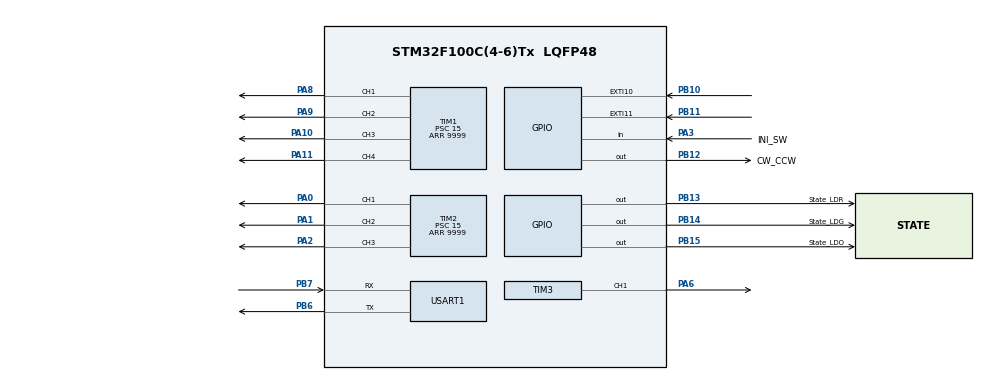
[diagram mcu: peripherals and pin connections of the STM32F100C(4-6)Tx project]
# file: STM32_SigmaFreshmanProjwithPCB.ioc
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Mcu.Family=STM32F1
Mcu.Name=STM32F100C(4-6)Tx
Mcu.Package=LQFP48
NVIC.EXTI15_10_IRQn=true\:0\:0\:false\:false\:true
NVIC.PriorityGroup=NVIC_PRIORITYGROUP_4
NVIC.TIM1_BRK_TIM15_IRQn=true\:0\:0\:false\:false\:true
NVIC.TIM1_UP_TIM16_IRQn=true\:0\:0\:false\:false\:true
NVIC.TIM2_IRQn=true\:0\:0\:false\:false\:true
NVIC.TIM3_IRQn=true\:0\:0\:false\:false\:true
NVIC.USART1_IRQn=true\:0\:0\:false\:false\:true
PA0-WKUP.Signal=S_TIM2_CH1_ETR
PA1.Signal=S_TIM2_CH2
PA10.Signal=S_TIM1_CH3
PA11.Signal=S_TIM1_CH4
PA13.Mode=Serial_Wire
PA13.Signal=SYS_JTMS-SWDIO
PA14.Mode=Serial_Wire
PA14.Signal=SYS_JTCK-SWCLK
PA2.Signal=S_TIM2_CH3
PA3.GPIO_Label=INI_SW
PA3.Signal=GPIO_Input
PA6.Signal=S_TIM3_CH1
PA8.Signal=S_TIM1_CH1
PA9.Signal=S_TIM1_CH2
PB10.GPIO_PuPd=GPIO_PULLUP
PB10.Signal=GPXTI10
PB11.GPIO_PuPd=GPIO_PULLUP
PB11.Signal=GPXTI11
PB12.GPIO_Label=CW_CCW
PB12.Signal=GPIO_Output
PB13.GPIO_Label=State_LDR
PB13.Signal=GPIO_Output
PB14.GPIO_Label=State_LDG
PB14.Signal=GPIO_Output
PB15.GPIO_Label=State_LDO
PB15.Signal=GPIO_Output
PB6.Mode=Asynchronous
PB6.Signal=USART1_TX
PB7.Mode=Asynchronous
PB7.Signal=USART1_RX
ProjectManager.HeapSize=0x200
ProjectManager.StackSize=0x400
ProjectManager.TargetToolchain=EWARM
RCC.APB1Freq_Value=8000000
RCC.APB2Freq_Value=8000000
SH.S_TIM1_CH1.0=TIM1_CH1,PWM Generation1 CH1
SH.S_TIM1_CH2.0=TIM1_CH2,PWM Generation2 CH2
SH.S_TIM1_CH3.0=TIM1_CH3,PWM Generation3 CH3
SH.S_TIM1_CH4.0=TIM1_CH4,PWM Generation4 CH4
SH.S_TIM2_CH1_ETR.0=TIM2_CH1,PWM Generation1 CH1
SH.S_TIM2_CH2.0=TIM2_CH2,PWM Generation2 CH2
SH.S_TIM2_CH3.0=TIM2_CH3,PWM Generation3 CH3
SH.S_TIM3_CH1.0=TIM3_CH1,PWM Generation1 CH1
TIM1.Channel-PWM\ Generation1\ CH1=TIM_CHANNEL_1
TIM1.Channel-PWM\ Generation2\ CH2=TIM_CHANNEL_2
TIM1.Channel-PWM\ Generation3\ CH3=TIM_CHANNEL_3
TIM1.Channel-PWM\ Generation4\ CH4=TIM_CHANNEL_4
TIM1.Period=9999
TIM1.Prescaler=15
TIM2.Channel-PWM\ Generation1\ CH1=TIM_CHANNEL_1
TIM2.Channel-PWM\ Generation2\ CH2=TIM_CHANNEL_2
TIM2.Channel-PWM\ Generation3\ CH3=TIM_CHANNEL_3
TIM2.Period=9999
TIM2.Prescaler=15
TIM3.Channel-PWM\ Generation1\ CH1=TIM_CHANNEL_1
TIM3.Period=99
TIM3.Prescaler=7999
USART1.VirtualMode=VM_ASYNC
board=STM32_SigmaFreshmanProjwithPCB

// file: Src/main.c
/**
  ******************************************************************************
  * File Name          : main.c
  * Description        : Main program body
  ******************************************************************************
  ** This notice applies to any and all portions of this file
  * that are not between comment pairs USER CODE BEGIN and
  * USER CODE END. Other portions of this file, whether
  * inserted by the user or by software development tools
  * are owned by their respective copyright owners.
  *
  * COPYRIGHT(c) 2017 STMicroelectronics
  *
  * Redistribution and use in source and binary forms, with or without modification,
  * are permitted provided that the following conditions are met:
  *   1. Redistributions of source code must retain the above copyright notice,
  *      this list of conditions and the following disclaimer.
  *   2. Redistributions in binary form must reproduce the above copyright notice,
  *      this list of conditions and the following disclaimer in the documentation
  *      and/or other materials provided with the distribution.
  *   3. Neither the name of STMicroelectronics nor the names of its contributors
  *      may be used to endorse or promote products derived from this software
  *      without specific prior written permission.
  *
  * THIS SOFTWARE IS PROVIDED BY THE COPYRIGHT HOLDERS AND CONTRIBUTORS "AS IS"
  * AND ANY EXPRESS OR IMPLIED WARRANTIES, INCLUDING, BUT NOT LIMITED TO, THE
  * IMPLIED WARRANTIES OF MERCHANTABILITY AND FITNESS FOR A PARTICULAR PURPOSE ARE
  * DISCLAIMED. IN NO EVENT SHALL THE COPYRIGHT HOLDER OR CONTRIBUTORS BE LIABLE
  * FOR ANY DIRECT, INDIRECT, INCIDENTAL, SPECIAL, EXEMPLARY, OR CONSEQUENTIAL
  * DAMAGES (INCLUDING, BUT NOT LIMITED TO, PROCUREMENT OF SUBSTITUTE GOODS OR
  * SERVICES; LOSS OF USE, DATA, OR PROFITS; OR BUSINESS INTERRUPTION) HOWEVER
  * CAUSED AND ON ANY THEORY OF LIABILITY, WHETHER IN CONTRACT, STRICT LIABILITY,
  * OR TORT (INCLUDING NEGLIGENCE OR OTHERWISE) ARISING IN ANY WAY OUT OF THE USE
  * OF THIS SOFTWARE, EVEN IF ADVISED OF THE POSSIBILITY OF SUCH DAMAGE.
  *
  ******************************************************************************
  */
#include "main.h"
#include "stm32f1xx_hal.h"

TIM_HandleTypeDef htim1;
TIM_HandleTypeDef htim2;
TIM_HandleTypeDef htim3;

UART_HandleTypeDef huart1;

/* USER CODE BEGIN PV */
/* Private variables ---------------------------------------------------------*/

/* USER CODE END PV */

void SystemClock_Config(void);
static void MX_GPIO_Init(void);
static void MX_TIM1_Init(void);
static void MX_USART1_UART_Init(void);
static void MX_TIM2_Init(void);
static void MX_TIM3_Init(void);
void HAL_TIM_MspPostInit(TIM_HandleTypeDef *htim);

/* USER CODE BEGIN PFP */
/* Private function prototypes -----------------------------------------------*/

/* USER CODE END PFP */

int main(void)
{

  /* MCU Configuration----------------------------------------------------------*/

  /* Reset of all peripherals, Initializes the Flash interface and the Systick. */
  HAL_Init();

  /* Configure the system clock */
  SystemClock_Config();

  /* Initialize all configured peripherals */
  MX_GPIO_Init();
  MX_TIM1_Init();
  MX_USART1_UART_Init();
  MX_TIM2_Init();
  MX_TIM3_Init();

  /* Infinite loop */
  /* USER CODE BEGIN WHILE */
  while (1)
  {
  	HAL_GPIO_TogglePin(State_LDO_GPIO_Port, State_LDO_Pin);
  	HAL_GPIO_TogglePin(State_LDR_GPIO_Port, State_LDR_Pin);
  	HAL_GPIO_TogglePin(State_LDG_GPIO_Port, State_LDG_Pin);
	HAL_Delay(1000);
  /* USER CODE END WHILE */

  }

}

/** System Clock Configuration
*/
void SystemClock_Config(void)
{

  RCC_OscInitTypeDef RCC_OscInitStruct;
  RCC_ClkInitTypeDef RCC_ClkInitStruct;

    /**Initializes the CPU, AHB and APB busses clocks
    */
  RCC_OscInitStruct.OscillatorType = RCC_OSCILLATORTYPE_HSI;
  RCC_OscInitStruct.HSIState = RCC_HSI_ON;
  RCC_OscInitStruct.HSICalibrationValue = 16;
  RCC_OscInitStruct.PLL.PLLState = RCC_PLL_NONE;
  if (HAL_RCC_OscConfig(&RCC_OscInitStruct) != HAL_OK)
  {
    _Error_Handler(__FILE__, __LINE__);
  }

    /**Initializes the CPU, AHB and APB busses clocks
    */
  RCC_ClkInitStruct.ClockType = RCC_CLOCKTYPE_HCLK|RCC_CLOCKTYPE_SYSCLK
                              |RCC_CLOCKTYPE_PCLK1|RCC_CLOCKTYPE_PCLK2;
  RCC_ClkInitStruct.SYSCLKSource = RCC_SYSCLKSOURCE_HSI;
  RCC_ClkInitStruct.AHBCLKDivider = RCC_SYSCLK_DIV1;
  RCC_ClkInitStruct.APB1CLKDivider = RCC_HCLK_DIV1;
  RCC_ClkInitStruct.APB2CLKDivider = RCC_HCLK_DIV1;

  if (HAL_RCC_ClockConfig(&RCC_ClkInitStruct, FLASH_LATENCY_0) != HAL_OK)
  {
    _Error_Handler(__FILE__, __LINE__);
  }

    /**Configure the Systick interrupt time
    */
  HAL_SYSTICK_Config(HAL_RCC_GetHCLKFreq()/1000);

    /**Configure the Systick
    */
  HAL_SYSTICK_CLKSourceConfig(SYSTICK_CLKSOURCE_HCLK);

  /* SysTick_IRQn interrupt configuration */
  HAL_NVIC_SetPriority(SysTick_IRQn, 0, 0);
}

/* TIM1 init function */
static void MX_TIM1_Init(void)
{

  TIM_MasterConfigTypeDef sMasterConfig;
  TIM_OC_InitTypeDef sConfigOC;
  TIM_BreakDeadTimeConfigTypeDef sBreakDeadTimeConfig;

  htim1.Instance = TIM1;
  htim1.Init.Prescaler = 15;
  htim1.Init.CounterMode = TIM_COUNTERMODE_UP;
  htim1.Init.Period = 9999;
  htim1.Init.ClockDivision = TIM_CLOCKDIVISION_DIV1;
  htim1.Init.RepetitionCounter = 0;
  htim1.Init.AutoReloadPreload = TIM_AUTORELOAD_PRELOAD_DISABLE;
  if (HAL_TIM_PWM_Init(&htim1) != HAL_OK)
  {
    _Error_Handler(__FILE__, __LINE__);
  }

  sMasterConfig.MasterOutputTrigger = TIM_TRGO_RESET;
  sMasterConfig.MasterSlaveMode = TIM_MASTERSLAVEMODE_DISABLE;
  if (HAL_TIMEx_MasterConfigSynchronization(&htim1, &sMasterConfig) != HAL_OK)
  {
    _Error_Handler(__FILE__, __LINE__);
  }

  sConfigOC.OCMode = TIM_OCMODE_PWM1;
  sConfigOC.Pulse = 0;
  sConfigOC.OCPolarity = TIM_OCPOLARITY_HIGH;
  sConfigOC.OCNPolarity = TIM_OCNPOLARITY_HIGH;
  sConfigOC.OCFastMode = TIM_OCFAST_DISABLE;
  sConfigOC.OCIdleState = TIM_OCIDLESTATE_RESET;
  sConfigOC.OCNIdleState = TIM_OCNIDLESTATE_RESET;
  if (HAL_TIM_PWM_ConfigChannel(&htim1, &sConfigOC, TIM_CHANNEL_1) != HAL_OK)
  {
    _Error_Handler(__FILE__, __LINE__);
  }

  if (HAL_TIM_PWM_ConfigChannel(&htim1, &sConfigOC, TIM_CHANNEL_2) != HAL_OK)
  {
    _Error_Handler(__FILE__, __LINE__);
  }

  if (HAL_TIM_PWM_ConfigChannel(&htim1, &sConfigOC, TIM_CHANNEL_3) != HAL_OK)
  {
    _Error_Handler(__FILE__, __LINE__);
  }

  if (HAL_TIM_PWM_ConfigChannel(&htim1, &sConfigOC, TIM_CHANNEL_4) != HAL_OK)
  {
    _Error_Handler(__FILE__, __LINE__);
  }

  sBreakDeadTimeConfig.OffStateRunMode = TIM_OSSR_DISABLE;
  sBreakDeadTimeConfig.OffStateIDLEMode = TIM_OSSI_DISABLE;
  sBreakDeadTimeConfig.LockLevel = TIM_LOCKLEVEL_OFF;
  sBreakDeadTimeConfig.DeadTime = 0;
  sBreakDeadTimeConfig.BreakState = TIM_BREAK_DISABLE;
  sBreakDeadTimeConfig.BreakPolarity = TIM_BREAKPOLARITY_HIGH;
  sBreakDeadTimeConfig.AutomaticOutput = TIM_AUTOMATICOUTPUT_DISABLE;
  if (HAL_TIMEx_ConfigBreakDeadTime(&htim1, &sBreakDeadTimeConfig) != HAL_OK)
  {
    _Error_Handler(__FILE__, __LINE__);
  }

  HAL_TIM_MspPostInit(&htim1);

}

/* TIM2 init function */
static void MX_TIM2_Init(void)
{

  TIM_MasterConfigTypeDef sMasterConfig;
  TIM_OC_InitTypeDef sConfigOC;

  htim2.Instance = TIM2;
  htim2.Init.Prescaler = 15;
  htim2.Init.CounterMode = TIM_COUNTERMODE_UP;
  htim2.Init.Period = 9999;
  htim2.Init.ClockDivision = TIM_CLOCKDIVISION_DIV1;
  htim2.Init.AutoReloadPreload = TIM_AUTORELOAD_PRELOAD_DISABLE;
  if (HAL_TIM_PWM_Init(&htim2) != HAL_OK)
  {
    _Error_Handler(__FILE__, __LINE__);
  }

  sMasterConfig.MasterOutputTrigger = TIM_TRGO_RESET;
  sMasterConfig.MasterSlaveMode = TIM_MASTERSLAVEMODE_DISABLE;
  if (HAL_TIMEx_MasterConfigSynchronization(&htim2, &sMasterConfig) != HAL_OK)
  {
    _Error_Handler(__FILE__, __LINE__);
  }

  sConfigOC.OCMode = TIM_OCMODE_PWM1;
  sConfigOC.Pulse = 0;
  sConfigOC.OCPolarity = TIM_OCPOLARITY_HIGH;
  sConfigOC.OCFastMode = TIM_OCFAST_DISABLE;
  if (HAL_TIM_PWM_ConfigChannel(&htim2, &sConfigOC, TIM_CHANNEL_1) != HAL_OK)
  {
    _Error_Handler(__FILE__, __LINE__);
  }

  if (HAL_TIM_PWM_ConfigChannel(&htim2, &sConfigOC, TIM_CHANNEL_2) != HAL_OK)
  {
    _Error_Handler(__FILE__, __LINE__);
  }

  if (HAL_TIM_PWM_ConfigChannel(&htim2, &sConfigOC, TIM_CHANNEL_3) != HAL_OK)
  {
    _Error_Handler(__FILE__, __LINE__);
  }

  HAL_TIM_MspPostInit(&htim2);

}

/* TIM3 init function */
static void MX_TIM3_Init(void)
{

  TIM_MasterConfigTypeDef sMasterConfig;
  TIM_OC_InitTypeDef sConfigOC;

  htim3.Instance = TIM3;
  htim3.Init.Prescaler = 7999;
  htim3.Init.CounterMode = TIM_COUNTERMODE_UP;
  htim3.Init.Period = 99;
  htim3.Init.ClockDivision = TIM_CLOCKDIVISION_DIV1;
  htim3.Init.AutoReloadPreload = TIM_AUTORELOAD_PRELOAD_DISABLE;
  if (HAL_TIM_PWM_Init(&htim3) != HAL_OK)
  {
    _Error_Handler(__FILE__, __LINE__);
  }

  sMasterConfig.MasterOutputTrigger = TIM_TRGO_RESET;
  sMasterConfig.MasterSlaveMode = TIM_MASTERSLAVEMODE_DISABLE;
  if (HAL_TIMEx_MasterConfigSynchronization(&htim3, &sMasterConfig) != HAL_OK)
  {
    _Error_Handler(__FILE__, __LINE__);
  }

  sConfigOC.OCMode = TIM_OCMODE_PWM1;
  sConfigOC.Pulse = 0;
  sConfigOC.OCPolarity = TIM_OCPOLARITY_HIGH;
  sConfigOC.OCFastMode = TIM_OCFAST_DISABLE;
  if (HAL_TIM_PWM_ConfigChannel(&htim3, &sConfigOC, TIM_CHANNEL_1) != HAL_OK)
  {
    _Error_Handler(__FILE__, __LINE__);
  }

  HAL_TIM_MspPostInit(&htim3);

}

/* USART1 init function */
static void MX_USART1_UART_Init(void)
{

  huart1.Instance = USART1;
  huart1.Init.BaudRate = 115200;
  huart1.Init.WordLength = UART_WORDLENGTH_8B;
  huart1.Init.StopBits = UART_STOPBITS_1;
  huart1.Init.Parity = UART_PARITY_NONE;
  huart1.Init.Mode = UART_MODE_TX_RX;
  huart1.Init.HwFlowCtl = UART_HWCONTROL_NONE;
  huart1.Init.OverSampling = UART_OVERSAMPLING_16;
  if (HAL_UART_Init(&huart1) != HAL_OK)
  {
    _Error_Handler(__FILE__, __LINE__);
  }

}

/** Configure pins as
        * Analog
        * Input
        * Output
        * EVENT_OUT
        * EXTI
*/
static void MX_GPIO_Init(void)
{

  GPIO_InitTypeDef GPIO_InitStruct;

  /* GPIO Ports Clock Enable */
  __HAL_RCC_GPIOA_CLK_ENABLE();
  __HAL_RCC_GPIOB_CLK_ENABLE();

  /*Configure GPIO pin Output Level */
  HAL_GPIO_WritePin(GPIOB, CW_CCW_Pin|State_LDR_Pin|State_LDG_Pin|State_LDO_Pin, GPIO_PIN_RESET);

  /*Configure GPIO pin : INI_SW_Pin */
  GPIO_InitStruct.Pin = INI_SW_Pin;
  GPIO_InitStruct.Mode = GPIO_MODE_INPUT;
  GPIO_InitStruct.Pull = GPIO_NOPULL;
  HAL_GPIO_Init(INI_SW_GPIO_Port, &GPIO_InitStruct);

  /*Configure GPIO pins : PB10 PB11 */
  GPIO_InitStruct.Pin = GPIO_PIN_10|GPIO_PIN_11;
  GPIO_InitStruct.Mode = GPIO_MODE_IT_RISING;
  GPIO_InitStruct.Pull = GPIO_PULLUP;
  HAL_GPIO_Init(GPIOB, &GPIO_InitStruct);

  /*Configure GPIO pins : CW_CCW_Pin State_LDR_Pin State_LDG_Pin State_LDO_Pin */
  GPIO_InitStruct.Pin = CW_CCW_Pin|State_LDR_Pin|State_LDG_Pin|State_LDO_Pin;
  GPIO_InitStruct.Mode = GPIO_MODE_OUTPUT_PP;
  GPIO_InitStruct.Speed = GPIO_SPEED_FREQ_LOW;
  HAL_GPIO_Init(GPIOB, &GPIO_InitStruct);

  /* EXTI interrupt init*/
  HAL_NVIC_SetPriority(EXTI15_10_IRQn, 0, 0);
  HAL_NVIC_EnableIRQ(EXTI15_10_IRQn);

}

void _Error_Handler(char * file, int line)
{
  while(1)
  {
  }
}

/************************ (C) COPYRIGHT STMicroelectronics *****END OF FILE****/
